# PIC32MX154F128D device description
Architecture: MIPS; Family: PIC32MX; Series: PIC32MX
Registers are 32-bit, read-write, no defined reset value unless marked. A register's access mark holds for its fields unless they carry their own. Offsets are from the block's base; [hi:lo] are bit positions.

## PORT
Instances: PORT 0x1f886000 in periph2
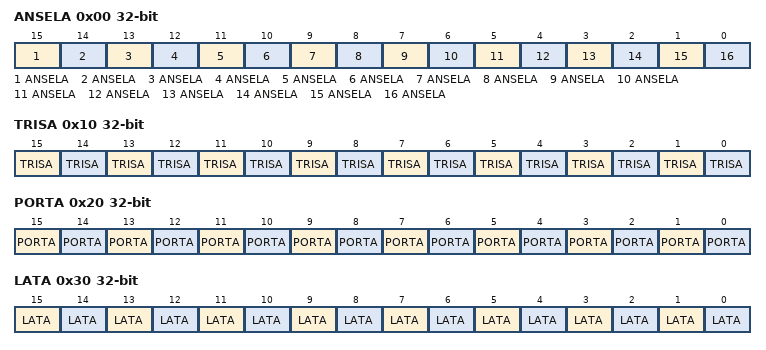
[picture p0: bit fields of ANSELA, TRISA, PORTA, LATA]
0x00 ANSELA
  [15] ANSELA, [14] ANSELA, [13] ANSELA, [12] ANSELA, [11] ANSELA, [10] ANSELA, [9] ANSELA, [8] ANSELA, [7] ANSELA, [6] ANSELA, [5] ANSELA, [4] ANSELA, [3] ANSELA, [2] ANSELA, [1] ANSELA, [0] ANSELA
0x10 TRISA
  [15] TRISA, [14] TRISA, [13] TRISA, [12] TRISA, [11] TRISA, [10] TRISA, [9] TRISA, [8] TRISA, [7] TRISA, [6] TRISA, [5] TRISA, [4] TRISA, [3] TRISA, [2] TRISA, [1] TRISA, [0] TRISA
0x20 PORTA
  [15] PORTA, [14] PORTA, [13] PORTA, [12] PORTA, [11] PORTA, [10] PORTA, [9] PORTA, [8] PORTA, [7] PORTA, [6] PORTA, [5] PORTA, [4] PORTA, [3] PORTA, [2] PORTA, [1] PORTA, [0] PORTA
0x30 LATA
  [15] LATA, [14] LATA, [13] LATA, [12] LATA, [11] LATA, [10] LATA, [9] LATA, [8] LATA, [7] LATA, [6] LATA, [5] LATA, [4] LATA, [3] LATA, [2] LATA, [1] LATA, [0] LATA
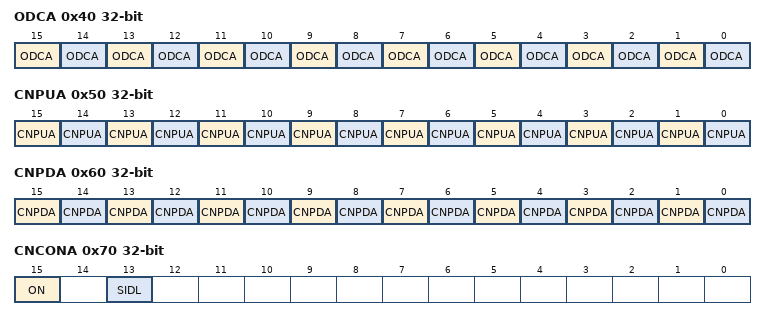
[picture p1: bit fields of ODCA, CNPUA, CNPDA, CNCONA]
0x40 ODCA
  [15] ODCA, [14] ODCA, [13] ODCA, [12] ODCA, [11] ODCA, [10] ODCA, [9] ODCA, [8] ODCA, [7] ODCA, [6] ODCA, [5] ODCA, [4] ODCA, [3] ODCA, [2] ODCA, [1] ODCA, [0] ODCA
0x50 CNPUA
  [15] CNPUA, [14] CNPUA, [13] CNPUA, [12] CNPUA, [11] CNPUA, [10] CNPUA, [9] CNPUA, [8] CNPUA, [7] CNPUA, [6] CNPUA, [5] CNPUA, [4] CNPUA, [3] CNPUA, [2] CNPUA, [1] CNPUA, [0] CNPUA
0x60 CNPDA
  [15] CNPDA, [14] CNPDA, [13] CNPDA, [12] CNPDA, [11] CNPDA, [10] CNPDA, [9] CNPDA, [8] CNPDA, [7] CNPDA, [6] CNPDA, [5] CNPDA, [4] CNPDA, [3] CNPDA, [2] CNPDA, [1] CNPDA, [0] CNPDA
0x70 CNCONA
  [15] ON, [13] SIDL
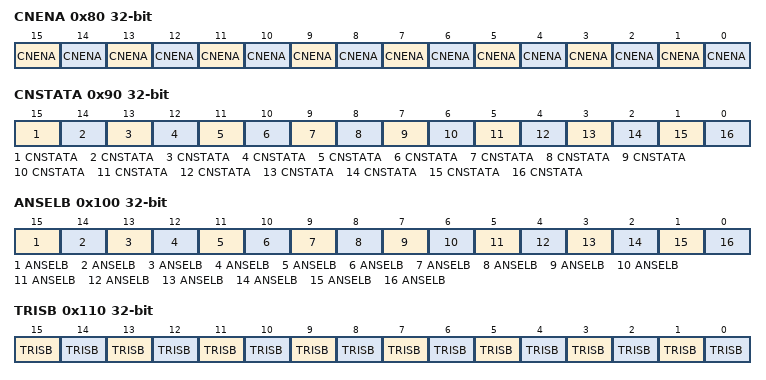
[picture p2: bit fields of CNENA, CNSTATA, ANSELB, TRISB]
0x80 CNENA
  [15] CNENA, [14] CNENA, [13] CNENA, [12] CNENA, [11] CNENA, [10] CNENA, [9] CNENA, [8] CNENA, [7] CNENA, [6] CNENA, [5] CNENA, [4] CNENA, [3] CNENA, [2] CNENA, [1] CNENA, [0] CNENA
0x90 CNSTATA
  [15] CNSTATA, [14] CNSTATA, [13] CNSTATA, [12] CNSTATA, [11] CNSTATA, [10] CNSTATA, [9] CNSTATA, [8] CNSTATA, [7] CNSTATA, [6] CNSTATA, [5] CNSTATA, [4] CNSTATA, [3] CNSTATA, [2] CNSTATA, [1] CNSTATA, [0] CNSTATA
0x100 ANSELB
  [15] ANSELB, [14] ANSELB, [13] ANSELB, [12] ANSELB, [11] ANSELB, [10] ANSELB, [9] ANSELB, [8] ANSELB, [7] ANSELB, [6] ANSELB, [5] ANSELB, [4] ANSELB, [3] ANSELB, [2] ANSELB, [1] ANSELB, [0] ANSELB
0x110 TRISB
  [15] TRISB, [14] TRISB, [13] TRISB, [12] TRISB, [11] TRISB, [10] TRISB, [9] TRISB, [8] TRISB, [7] TRISB, [6] TRISB, [5] TRISB, [4] TRISB, [3] TRISB, [2] TRISB, [1] TRISB, [0] TRISB
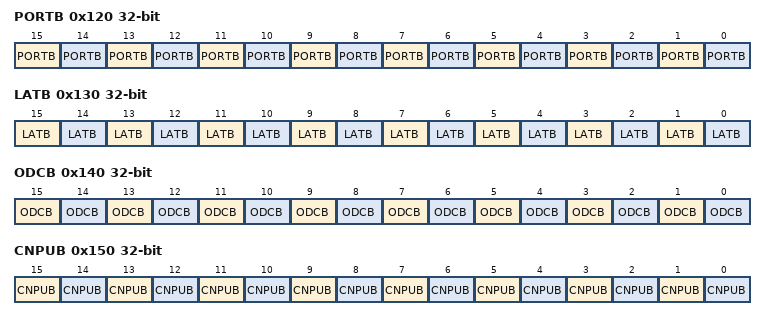
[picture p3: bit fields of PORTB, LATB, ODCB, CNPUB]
0x120 PORTB
  [15] PORTB, [14] PORTB, [13] PORTB, [12] PORTB, [11] PORTB, [10] PORTB, [9] PORTB, [8] PORTB, [7] PORTB, [6] PORTB, [5] PORTB, [4] PORTB, [3] PORTB, [2] PORTB, [1] PORTB, [0] PORTB
0x130 LATB
  [15] LATB, [14] LATB, [13] LATB, [12] LATB, [11] LATB, [10] LATB, [9] LATB, [8] LATB, [7] LATB, [6] LATB, [5] LATB, [4] LATB, [3] LATB, [2] LATB, [1] LATB, [0] LATB
0x140 ODCB
  [15] ODCB, [14] ODCB, [13] ODCB, [12] ODCB, [11] ODCB, [10] ODCB, [9] ODCB, [8] ODCB, [7] ODCB, [6] ODCB, [5] ODCB, [4] ODCB, [3] ODCB, [2] ODCB, [1] ODCB, [0] ODCB
0x150 CNPUB
  [15] CNPUB, [14] CNPUB, [13] CNPUB, [12] CNPUB, [11] CNPUB, [10] CNPUB, [9] CNPUB, [8] CNPUB, [7] CNPUB, [6] CNPUB, [5] CNPUB, [4] CNPUB, [3] CNPUB, [2] CNPUB, [1] CNPUB, [0] CNPUB
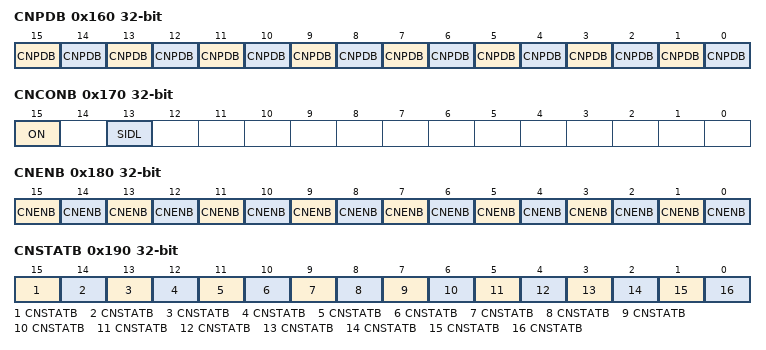
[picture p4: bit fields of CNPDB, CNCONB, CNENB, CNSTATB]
0x160 CNPDB
  [15] CNPDB, [14] CNPDB, [13] CNPDB, [12] CNPDB, [11] CNPDB, [10] CNPDB, [9] CNPDB, [8] CNPDB, [7] CNPDB, [6] CNPDB, [5] CNPDB, [4] CNPDB, [3] CNPDB, [2] CNPDB, [1] CNPDB, [0] CNPDB
0x170 CNCONB
  [15] ON, [13] SIDL
0x180 CNENB
  [15] CNENB, [14] CNENB, [13] CNENB, [12] CNENB, [11] CNENB, [10] CNENB, [9] CNENB, [8] CNENB, [7] CNENB, [6] CNENB, [5] CNENB, [4] CNENB, [3] CNENB, [2] CNENB, [1] CNENB, [0] CNENB
0x190 CNSTATB
  [15] CNSTATB, [14] CNSTATB, [13] CNSTATB, [12] CNSTATB, [11] CNSTATB, [10] CNSTATB, [9] CNSTATB, [8] CNSTATB, [7] CNSTATB, [6] CNSTATB, [5] CNSTATB, [4] CNSTATB, [3] CNSTATB, [2] CNSTATB, [1] CNSTATB, [0] CNSTATB
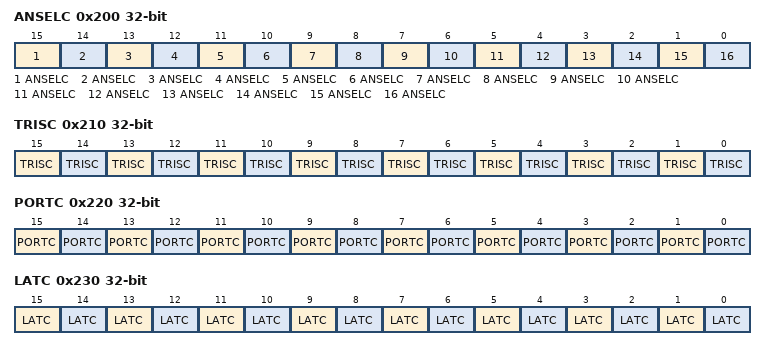
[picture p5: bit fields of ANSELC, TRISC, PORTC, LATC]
0x200 ANSELC
  [15] ANSELC, [14] ANSELC, [13] ANSELC, [12] ANSELC, [11] ANSELC, [10] ANSELC, [9] ANSELC, [8] ANSELC, [7] ANSELC, [6] ANSELC, [5] ANSELC, [4] ANSELC, [3] ANSELC, [2] ANSELC, [1] ANSELC, [0] ANSELC
0x210 TRISC
  [15] TRISC, [14] TRISC, [13] TRISC, [12] TRISC, [11] TRISC, [10] TRISC, [9] TRISC, [8] TRISC, [7] TRISC, [6] TRISC, [5] TRISC, [4] TRISC, [3] TRISC, [2] TRISC, [1] TRISC, [0] TRISC
0x220 PORTC
  [15] PORTC, [14] PORTC, [13] PORTC, [12] PORTC, [11] PORTC, [10] PORTC, [9] PORTC, [8] PORTC, [7] PORTC, [6] PORTC, [5] PORTC, [4] PORTC, [3] PORTC, [2] PORTC, [1] PORTC, [0] PORTC
0x230 LATC
  [15] LATC, [14] LATC, [13] LATC, [12] LATC, [11] LATC, [10] LATC, [9] LATC, [8] LATC, [7] LATC, [6] LATC, [5] LATC, [4] LATC, [3] LATC, [2] LATC, [1] LATC, [0] LATC
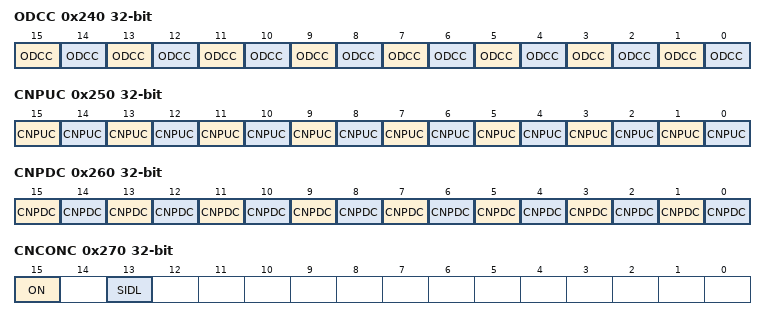
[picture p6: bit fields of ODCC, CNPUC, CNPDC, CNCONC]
0x240 ODCC
  [15] ODCC, [14] ODCC, [13] ODCC, [12] ODCC, [11] ODCC, [10] ODCC, [9] ODCC, [8] ODCC, [7] ODCC, [6] ODCC, [5] ODCC, [4] ODCC, [3] ODCC, [2] ODCC, [1] ODCC, [0] ODCC
0x250 CNPUC
  [15] CNPUC, [14] CNPUC, [13] CNPUC, [12] CNPUC, [11] CNPUC, [10] CNPUC, [9] CNPUC, [8] CNPUC, [7] CNPUC, [6] CNPUC, [5] CNPUC, [4] CNPUC, [3] CNPUC, [2] CNPUC, [1] CNPUC, [0] CNPUC
0x260 CNPDC
  [15] CNPDC, [14] CNPDC, [13] CNPDC, [12] CNPDC, [11] CNPDC, [10] CNPDC, [9] CNPDC, [8] CNPDC, [7] CNPDC, [6] CNPDC, [5] CNPDC, [4] CNPDC, [3] CNPDC, [2] CNPDC, [1] CNPDC, [0] CNPDC
0x270 CNCONC
  [15] ON, [13] SIDL
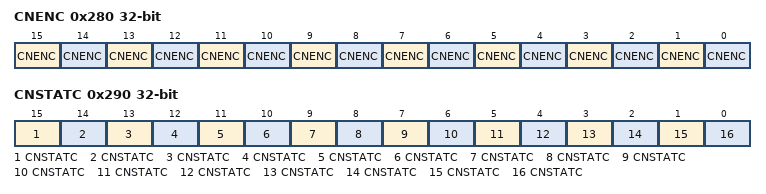
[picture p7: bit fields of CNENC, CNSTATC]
0x280 CNENC
  [15] CNENC, [14] CNENC, [13] CNENC, [12] CNENC, [11] CNENC, [10] CNENC, [9] CNENC, [8] CNENC, [7] CNENC, [6] CNENC, [5] CNENC, [4] CNENC, [3] CNENC, [2] CNENC, [1] CNENC, [0] CNENC
0x290 CNSTATC
  [15] CNSTATC, [14] CNSTATC, [13] CNSTATC, [12] CNSTATC, [11] CNSTATC, [10] CNSTATC, [9] CNSTATC, [8] CNSTATC, [7] CNSTATC, [6] CNSTATC, [5] CNSTATC, [4] CNSTATC, [3] CNSTATC, [2] CNSTATC, [1] CNSTATC, [0] CNSTATC
